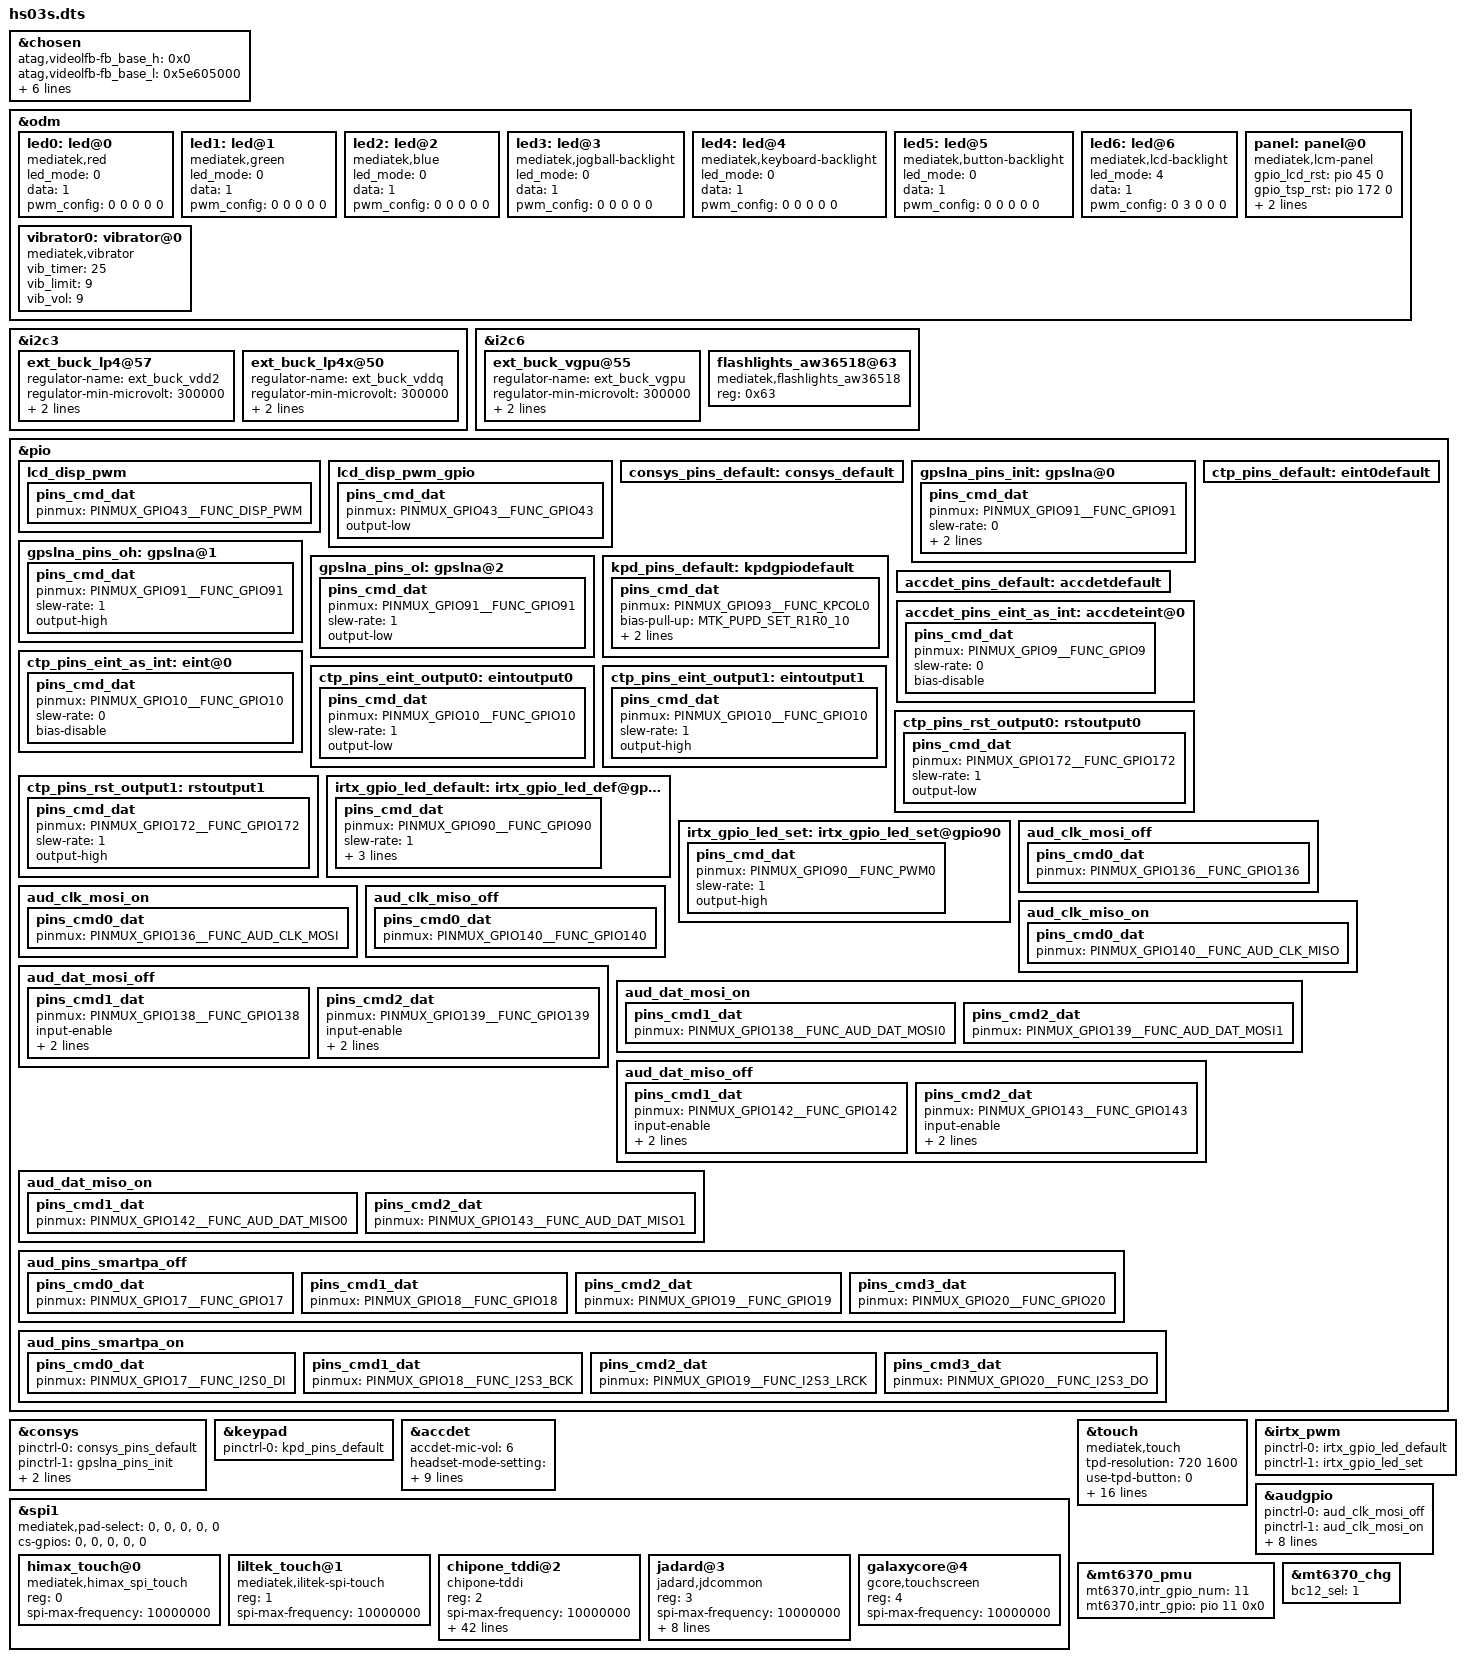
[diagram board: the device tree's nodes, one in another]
// SPDX-License-Identifier: GPL-2.0+
/*
 * Copyright (c) 2019 MediaTek Inc.
 *
 */

#include <dt-bindings/interrupt-controller/arm-gic.h>
#include <dt-bindings/interrupt-controller/irq.h>
#include <dt-bindings/pinctrl/mt6765-pinfunc.h>
#include <dt-bindings/clock/mt6765-clk.h>
#include <dt-bindings/mmc/mt6765-msdc.h>

/* chosen */
&chosen {

	/* fpga may has no lk, we need to specify display info here */
	/* fb buffer is reserved using this dts by memory node above */
	atag,videolfb-fb_base_h = <0x0>;
	atag,videolfb-fb_base_l = <0x5e605000>;
	atag,videolfb-islcmfound = <1>;
	/* because no lk, so lcm is not inited */
	atag,videolfb-islcm_inited = <0>;
	atag,videolfb-fps= <6000>;
	atag,videolfb-vramSize= <0x017bb000>;
	atag,videolfb-lcmname= "nt35695B_fhd_dsi_cmd_auo_rt5081_drv";
};

&odm {
	led0:led@0 {
		compatible = "mediatek,red";
		led_mode = <0>;
		data = <1>;
		pwm_config = <0 0 0 0 0>;
	};
	led1:led@1 {
		compatible = "mediatek,green";
		led_mode = <0>;
		data = <1>;
		pwm_config = <0 0 0 0 0>;
	};
	led2:led@2 {
		compatible = "mediatek,blue";
		led_mode = <0>;
		data = <1>;
		pwm_config = <0 0 0 0 0>;
	};
	led3:led@3 {
		compatible = "mediatek,jogball-backlight";
		led_mode = <0>;
		data = <1>;
		pwm_config = <0 0 0 0 0>;
	};
	led4:led@4 {
		compatible = "mediatek,keyboard-backlight";
		led_mode = <0>;
		data = <1>;
		pwm_config = <0 0 0 0 0>;
	};
	led5:led@5 {
		compatible = "mediatek,button-backlight";
		led_mode = <0>;
		data = <1>;
		pwm_config = <0 0 0 0 0>;
	};
	
	/* HS03S code added for SR-AL5625-01-310 by gaozhengwei at 20210423 start */
	led6:led@6 {
		compatible = "mediatek,lcd-backlight";
		led_mode = <4>;
		data = <1>;
		pwm_config = <0 3 0 0 0>;
	};
	panel: panel@0 {
		compatible = "mediatek,lcm-panel";
		gpio_lcd_rst = <&pio 45 0>;
		/* hs03s_NM code added for SR-AL5625-01-609 by fengzhigang at 20220424 start */
		gpio_tsp_rst = <&pio 172 0>;
		pinctrl-names = "disp_pwm", "disp_pwm_gpio";
		pinctrl-0 = <&lcd_disp_pwm>;
		pinctrl-1 = <&lcd_disp_pwm_gpio>;
		/* hs03s_NM code added for SR-AL5625-01-609 by fengzhigang at 20220424 end */
	};
	/* HS03S code added for SR-AL5625-01-310 by gaozhengwei at 20210423 end */
	
	vibrator0:vibrator@0 {
		compatible = "mediatek,vibrator";
		vib_timer = <25>;
		vib_limit = <9>;
		vib_vol= <9>;
	};
};

&i2c3 {
	ext_buck_lp4@57 {
		regulator-name ="ext_buck_vdd2";
		regulator-min-microvolt = <300000>;
		regulator-max-microvolt = <1300000>;
		vsel_pin = <0>;
	};

	ext_buck_lp4x@50 {
		regulator-name ="ext_buck_vddq";
		regulator-min-microvolt = <300000>;
		regulator-max-microvolt = <1300000>;
		vsel_pin = <1>;
	};
};

&i2c6 {
	ext_buck_vgpu@55 {
		regulator-name ="ext_buck_vgpu";
		regulator-min-microvolt = <300000>;
		regulator-max-microvolt = <1300000>;
		vsel_pin = <2>;
	};
};
/*hs03s code add for flashlights_aw36518 by chengzhi at 2021.06.13 begin*/
&i2c6 {
    flashlights_aw36518@63 {
        compatible = "mediatek,flashlights_aw36518";
        reg = <0x63>;
        status = "okay";
    };
};
/*hs03s code add for flashlights_aw36518 by chengzhi at 2021.06.13 end*/

/* CONSYS GPIO standardization */
&pio {
	/* HS03S code added for SR-AL5625-01-310 by gaozhengwei at 20210423 start */
	lcd_disp_pwm: lcd_disp_pwm {
		pins_cmd_dat {
			pinmux = <PINMUX_GPIO43__FUNC_DISP_PWM>;
		};
	};

	lcd_disp_pwm_gpio: lcd_disp_pwm_gpio {
		pins_cmd_dat {
			pinmux = <PINMUX_GPIO43__FUNC_GPIO43>;
			output-low;
		};
	};
	/* HS03S code added for SR-AL5625-01-310 by gaozhengwei at 20210423 end */
	
	consys_pins_default: consys_default {
	};
	gpslna_pins_init: gpslna@0 {
		pins_cmd_dat {
			pinmux = <PINMUX_GPIO91__FUNC_GPIO91>;
			slew-rate = <0>;
			bias-disable;
			output-low;
		};
	};
	gpslna_pins_oh: gpslna@1 {
		pins_cmd_dat {
			pinmux = <PINMUX_GPIO91__FUNC_GPIO91>;
			slew-rate = <1>;
			output-high;
		};
	};
	gpslna_pins_ol: gpslna@2 {
		pins_cmd_dat {
			pinmux = <PINMUX_GPIO91__FUNC_GPIO91>;
			slew-rate = <1>;
			output-low;
		};
	};
};
&consys {
	pinctrl-names = "default", "gps_lna_state_init",
		"gps_lna_state_oh", "gps_lna_state_ol";
	pinctrl-0 = <&consys_pins_default>;
	pinctrl-1 = <&gpslna_pins_init>;
	pinctrl-2 = <&gpslna_pins_oh>;
	pinctrl-3 = <&gpslna_pins_ol>;
	status = "okay";
};
/* CONSYS end */

&keypad {
	pinctrl-names = "default";
	pinctrl-0 = <&kpd_pins_default>;
};

&pio {
	kpd_pins_default: kpdgpiodefault {
		pins_cmd_dat {
			pinmux = <PINMUX_GPIO93__FUNC_KPCOL0>;
			bias-pull-up = <MTK_PUPD_SET_R1R0_10>;
			output-low;
			input-schmitt-enable;
		};
	};
};


/* accdet start */
&accdet {
	accdet-mic-vol = <6>;
	headset-mode-setting = <0x500 0x500 1 0x1f0 0x800 0x800 0x20 0x44>;
	accdet-plugout-debounce = <1>;
	accdet-mic-mode = <1>;
	headset-eint-level-pol = <8>;
	headset-three-key-threshold = <0 80 220 400>;
	headset-three-key-threshold-CDD = <0 121 192 600>;
	headset-four-key-threshold = <0 58 121 192 400>;
	pinctrl-names = "default", "state_eint_as_int";
	pinctrl-0 = <&accdet_pins_default>;
	pinctrl-1 = <&accdet_pins_eint_as_int>;
	status = "okay";
};
&pio {
	accdet_pins_default: accdetdefault {
	};
	accdet_pins_eint_as_int: accdeteint@0 {
		pins_cmd_dat {
			pinmux = <PINMUX_GPIO9__FUNC_GPIO9>;
			slew-rate = <0>;
			bias-disable;
		};
	};
};
/* accdet end */


&spi1 {
	status = "okay";
	#address-cells = <1>;
	#size-cells = <0>;
	/delete-property/mediatek,pad-select;
	mediatek,pad-select = <0>, <0>, <0>, <0>, <0>;
	cs-gpios = <0>, <0>, <0>, <0>, <0>;

	himax_touch@0 {
		compatible = "mediatek,himax_spi_touch";
		reg = <0>;
		status = "okay";
		spi-max-frequency = <10000000>;
	};

	liltek_touch@1 {
		compatible = "mediatek,ilitek-spi-touch";
		reg = <1>;
		status = "okay";
		spi-max-frequency = <10000000>;
	};

	chipone_tddi@2 {
        compatible = "chipone-tddi";
        reg = <2>;
		status = "okay";
		spi-max-frequency = <10000000>;

        /* Charger detect */
        chipone,touch-charger-detect-enable;
        chipone,touch-charger-detect-type = "notify"; /* notify, poll */
        chipone,touch-charger-detect-psy-name = "mtk_charger_type";
        chipone,touch-charger-detect-psp = "POWER_SUPPLY_PROP_ONLINE";
        chipone,touch-charger-detect-psp-poll-interval = <1000>;

        /* Earjack detect */
        chipone,touch-earjack-detect-enable;
        /* MTK:  /sys/bus/platform/drivers/Accdet_Driver/state,
           Sprd: /sys/kernel/headset/state
           QCOM: None, and disable it */
        chipone,touch-earjack-state-filepath = "/sys/bus/platform/drivers/Accdet_Driver/state";
        chipone,touch-earjack-poll-interval = <1000>;

		/*hs03s_NM code for SR-AL5625-01-641 by yuli at 2022/4/24 start*/
		/* selftest settings */
		chipone_xl_truly,test-reset-pin;
		//chipone_xl_truly,test-int-pin;

		chipone_xl_truly,test-rawdata;
		chipone_xl_truly,test-rawdata-frames = <1>;
		chipone_xl_truly,rawdata-min = <1500>;//base 2200
		chipone_xl_truly,rawdata-max = <2900>;

		chipone_xl_truly,test-noise;
		chipone_xl_truly,test-noise-frames = <16>;
		chipone_xl_truly,noise-max = <100>;

		chipone_xl_truly,test-open;
		chipone_xl_truly,open-min = <3100>;

		chipone_xl_truly,test-short;
		chipone_xl_truly,short-min = <500>;

		chipone_xl_truly,test-compensate-cap;
		chipone_xl_truly,compensate-cap-min = <1>;
		chipone_xl_truly,compensate-cap-max = <126>;

		/* txd_hkc selftest settings */
		chipone_txd_hkc,test-reset-pin;
		//chipone_txd_hkc,test-int-pin;

		chipone_txd_hkc,test-rawdata;
		chipone_txd_hkc,test-rawdata-frames = <1>;
		chipone_txd_hkc,rawdata-min = <1300>;//base 2200
		chipone_txd_hkc,rawdata-max = <2700>;

		chipone_txd_hkc,test-noise;
		chipone_txd_hkc,test-noise-frames = <50>;
		chipone_txd_hkc,noise-max = <76>;

		chipone_txd_hkc,test-open;
		chipone_txd_hkc,open-min = <2770>;

		chipone_txd_hkc,test-short;
		chipone_txd_hkc,short-min = <500>;

		chipone_txd_hkc,test-compensate-cap;
		chipone_txd_hkc,compensate-cap-min = <1>;
		chipone_txd_hkc,compensate-cap-max = <126>;
		/*hs03s_NM code for SR-AL5625-01-641 by yuli at 2022/4/24 end*/
    };
	
	jadard@3 {
		compatible = "jadard,jdcommon";
		reg = <3>;
		spi-max-frequency = <10000000>;
		interrupt-parent = <&pio>;
		interrupts = <10 0x2800>;
		jadard,panel-sense-nums = <18 32>;
		jadard,panel-coords = <0 720 0 1600>;
		jadard,panel-max-points = <10>;
		jadard,int-is-edge = <1>;
		jadard,irq-gpio = <&pio 10 0x2008>;
		jadard,rst-gpio = <&pio 172 0x00>;

	};

	/*hs03s_NM code for SR-AL5625-01-644 by fengzhigang at 20220414 start*/
	galaxycore@4 {
		compatible = "gcore,touchscreen";
		reg = <4>;
		status = "okay";
		spi-max-frequency = <10000000>;
	};
	/*hs03s_NM code for SR-AL5625-01-644 by fengzhigang at 20220414 end*/
};

/* TOUCH start */
&touch {
	/delete-property/ compatible;
	compatible = "mediatek,touch";

	tpd-resolution = <720 1600>;
	use-tpd-button = <0>;
	tpd-key-num = <3>;
	tpd-key-local= <139 172 158 0>;
	tpd-key-dim-local = <90 883 100 40 230
				 883 100 40 370 883 100 40 0 0 0 0>;
	tpd-max-touch-num = <10>;
	tpd-filter-enable = <0>;
	tpd-filter-pixel-density = <106>;
	tpd-filter-custom-prameters = <0 0 0 0 0 0 0 0 0 0 0 0>;
	tpd-filter-custom-speed = <0 0 0>;
	pinctrl-names = "default", "state_eint_as_int", "state_eint_output0",
		"state_eint_output1", "state_rst_output0", "state_rst_output1";
	pinctrl-0 = <&ctp_pins_default>;
	pinctrl-1 = <&ctp_pins_eint_as_int>;
	pinctrl-2 = <&ctp_pins_eint_output0>;
	pinctrl-3 = <&ctp_pins_eint_output1>;
	pinctrl-4 = <&ctp_pins_rst_output0>;
	pinctrl-5 = <&ctp_pins_rst_output1>;
	status = "okay";
};
&pio {
	ctp_pins_default: eint0default {
	};
	ctp_pins_eint_as_int: eint@0 {
		pins_cmd_dat {
			pinmux = <PINMUX_GPIO10__FUNC_GPIO10>;
			slew-rate = <0>;
			bias-disable;
		};
	};
	ctp_pins_eint_output0: eintoutput0 {
		pins_cmd_dat {
			pinmux = <PINMUX_GPIO10__FUNC_GPIO10>;
			slew-rate = <1>;
			output-low;
		};
	};
	ctp_pins_eint_output1: eintoutput1 {
		pins_cmd_dat {
			pinmux = <PINMUX_GPIO10__FUNC_GPIO10>;
			slew-rate = <1>;
			output-high;
		};
	};
	ctp_pins_rst_output0: rstoutput0 {
		pins_cmd_dat {
			pinmux = <PINMUX_GPIO172__FUNC_GPIO172>;
			slew-rate = <1>;
			output-low;
		};
	};
	ctp_pins_rst_output1: rstoutput1 {
		pins_cmd_dat {
			pinmux = <PINMUX_GPIO172__FUNC_GPIO172>;
			slew-rate = <1>;
			output-high;
		};
	};
};


/* IRTX GPIO end */
&irtx_pwm {
	pinctrl-names = "irtx_gpio_led_default", "irtx_gpio_led_set";
	pinctrl-0 = <&irtx_gpio_led_default>;
	pinctrl-1 = <&irtx_gpio_led_set>;
	status = "okay";
};
&pio {
	irtx_gpio_led_default:irtx_gpio_led_def@gpio90 {
		pins_cmd_dat {
			pinmux = <PINMUX_GPIO90__FUNC_GPIO90>;
			slew-rate = <1>;
			bias-disable;
			output-low;
			input-schmitt-enable = <0>;
		};
	};

	irtx_gpio_led_set:irtx_gpio_led_set@gpio90 {
		pins_cmd_dat {
			pinmux = <PINMUX_GPIO90__FUNC_PWM0>;
			slew-rate = <1>;
			output-high;
		};
	};
};
/* IRTX GPIO Settings -End */

/* AUDIO GPIO standardization */
&audgpio {
	pinctrl-names = "aud_clk_mosi_off",
			"aud_clk_mosi_on",
			"aud_clk_miso_off",
			"aud_clk_miso_on",
			"aud_dat_mosi_off",
			"aud_dat_mosi_on",
			"aud_dat_miso_off",
			"aud_dat_miso_on",
			"aud_smartpa_off",
			"aud_smartpa_on";
	pinctrl-0 = <&aud_clk_mosi_off>;
	pinctrl-1 = <&aud_clk_mosi_on>;
	pinctrl-2 = <&aud_clk_miso_off>;
	pinctrl-3 = <&aud_clk_miso_on>;
	pinctrl-4 = <&aud_dat_mosi_off>;
	pinctrl-5 = <&aud_dat_mosi_on>;
	pinctrl-6 = <&aud_dat_miso_off>;
	pinctrl-7 = <&aud_dat_miso_on>;
	pinctrl-8 = <&aud_pins_smartpa_off>;
	pinctrl-9 = <&aud_pins_smartpa_on>;
	status = "okay";
};

&pio {
	aud_clk_mosi_off: aud_clk_mosi_off {
		pins_cmd0_dat {
			pinmux = <PINMUX_GPIO136__FUNC_GPIO136>;
		};
	};

	aud_clk_mosi_on: aud_clk_mosi_on {
		pins_cmd0_dat {
			pinmux = <PINMUX_GPIO136__FUNC_AUD_CLK_MOSI>;
		};
	};

	aud_clk_miso_off: aud_clk_miso_off {
		pins_cmd0_dat {
			pinmux = <PINMUX_GPIO140__FUNC_GPIO140>;
		};
	};

	aud_clk_miso_on: aud_clk_miso_on {
		pins_cmd0_dat {
			pinmux = <PINMUX_GPIO140__FUNC_AUD_CLK_MISO>;
		};
	};

	aud_dat_mosi_off: aud_dat_mosi_off {
		pins_cmd1_dat {
			pinmux = <PINMUX_GPIO138__FUNC_GPIO138>;
			input-enable;
			slew-rate = <0>;
			bias-disable;
		};
		pins_cmd2_dat {
			pinmux = <PINMUX_GPIO139__FUNC_GPIO139>;
			input-enable;
			slew-rate = <0>;
			bias-disable;
		};
	};

	aud_dat_mosi_on: aud_dat_mosi_on {
		pins_cmd1_dat {
			pinmux = <PINMUX_GPIO138__FUNC_AUD_DAT_MOSI0>;
		};
		pins_cmd2_dat {
			pinmux = <PINMUX_GPIO139__FUNC_AUD_DAT_MOSI1>;
		};
	};

	aud_dat_miso_off: aud_dat_miso_off {
		pins_cmd1_dat {
			pinmux = <PINMUX_GPIO142__FUNC_GPIO142>;
			input-enable;
			slew-rate = <0>;
			bias-disable;
		};
		pins_cmd2_dat {
			pinmux = <PINMUX_GPIO143__FUNC_GPIO143>;
			input-enable;
			slew-rate = <0>;
			bias-disable;
		};
	};

	aud_dat_miso_on: aud_dat_miso_on {
		pins_cmd1_dat {
			pinmux = <PINMUX_GPIO142__FUNC_AUD_DAT_MISO0>;
		};
		pins_cmd2_dat {
			pinmux = <PINMUX_GPIO143__FUNC_AUD_DAT_MISO1>;
		};
	};

	aud_pins_smartpa_off: aud_pins_smartpa_off {
		pins_cmd0_dat {
			pinmux = <PINMUX_GPIO17__FUNC_GPIO17>;
		};
		pins_cmd1_dat {
			pinmux = <PINMUX_GPIO18__FUNC_GPIO18>;
		};
		pins_cmd2_dat {
			pinmux = <PINMUX_GPIO19__FUNC_GPIO19>;
		};
		pins_cmd3_dat {
			pinmux = <PINMUX_GPIO20__FUNC_GPIO20>;
		};
	};

	aud_pins_smartpa_on: aud_pins_smartpa_on {
		pins_cmd0_dat {
			pinmux = <PINMUX_GPIO17__FUNC_I2S0_DI>;
		};
		pins_cmd1_dat {
			pinmux = <PINMUX_GPIO18__FUNC_I2S3_BCK>;
		};
		pins_cmd2_dat {
			pinmux = <PINMUX_GPIO19__FUNC_I2S3_LRCK>;
		};
		pins_cmd3_dat {
			pinmux = <PINMUX_GPIO20__FUNC_I2S3_DO>;
		};
	};
};
/* AUDIO end */

&mt6370_pmu {
	mt6370,intr_gpio_num = <11>; /* direct defined GPIO num */
	mt6370,intr_gpio = <&pio 11 0x0>;
};

/*HS03s for SR-AL5625-01-515 by wangzikang at 20210607 start*/
//&mt6370_typec {
//	mt6370pd,intr_gpio_num = <41>; /* direct defined GPIO num */
//	mt6370pd,intr_gpio = <&pio 41 0x0>;
//};
/*HS03s for SR-AL5625-01-515 by wangzikang at 20210607 end*/

&mt6370_chg {
	bc12_sel = <1>;
};
/* #include <hs03s/cust.dtsi> */
#include "mediatek/hs03s/cust.dtsi"
#include "mediatek/hs03s/hs03s-common.dtsi"
#include "mediatek/cust_mt6765_camera.dtsi"
/*End of this file, DO NOT ADD ANYTHING HERE*/
